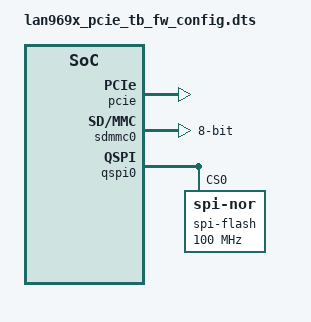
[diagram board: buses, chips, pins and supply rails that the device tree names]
/*
 * Copyright (c) 2022, Microchip Technology Inc. and its subsidiaries.
 *
 * SPDX-License-Identifier: BSD-3-Clause
 */

/dts-v1/;

#include "lan969x.dtsi"
#include "lan969x-ddr.dtsi"

&emmc_clk {
	clock-frequency = <104000000>;
};

&sdmmc0 {
	status = "okay";
	bus-width = <8>;
};

&qspi0 {
	status = "okay";
	spi-flash@0 {
		compatible = "jedec,spi-nor";
		reg = <0>;
		spi-max-frequency = <100000000>;
		spi-tx-bus-width = <4>;
		spi-rx-bus-width = <4>;
	};
};

/ {
	pcie: pcie@e00d0000 {
		compatible = "microchip,pcie-ep";
		microchip,perst_gpio = <0 2>;
	};
};
